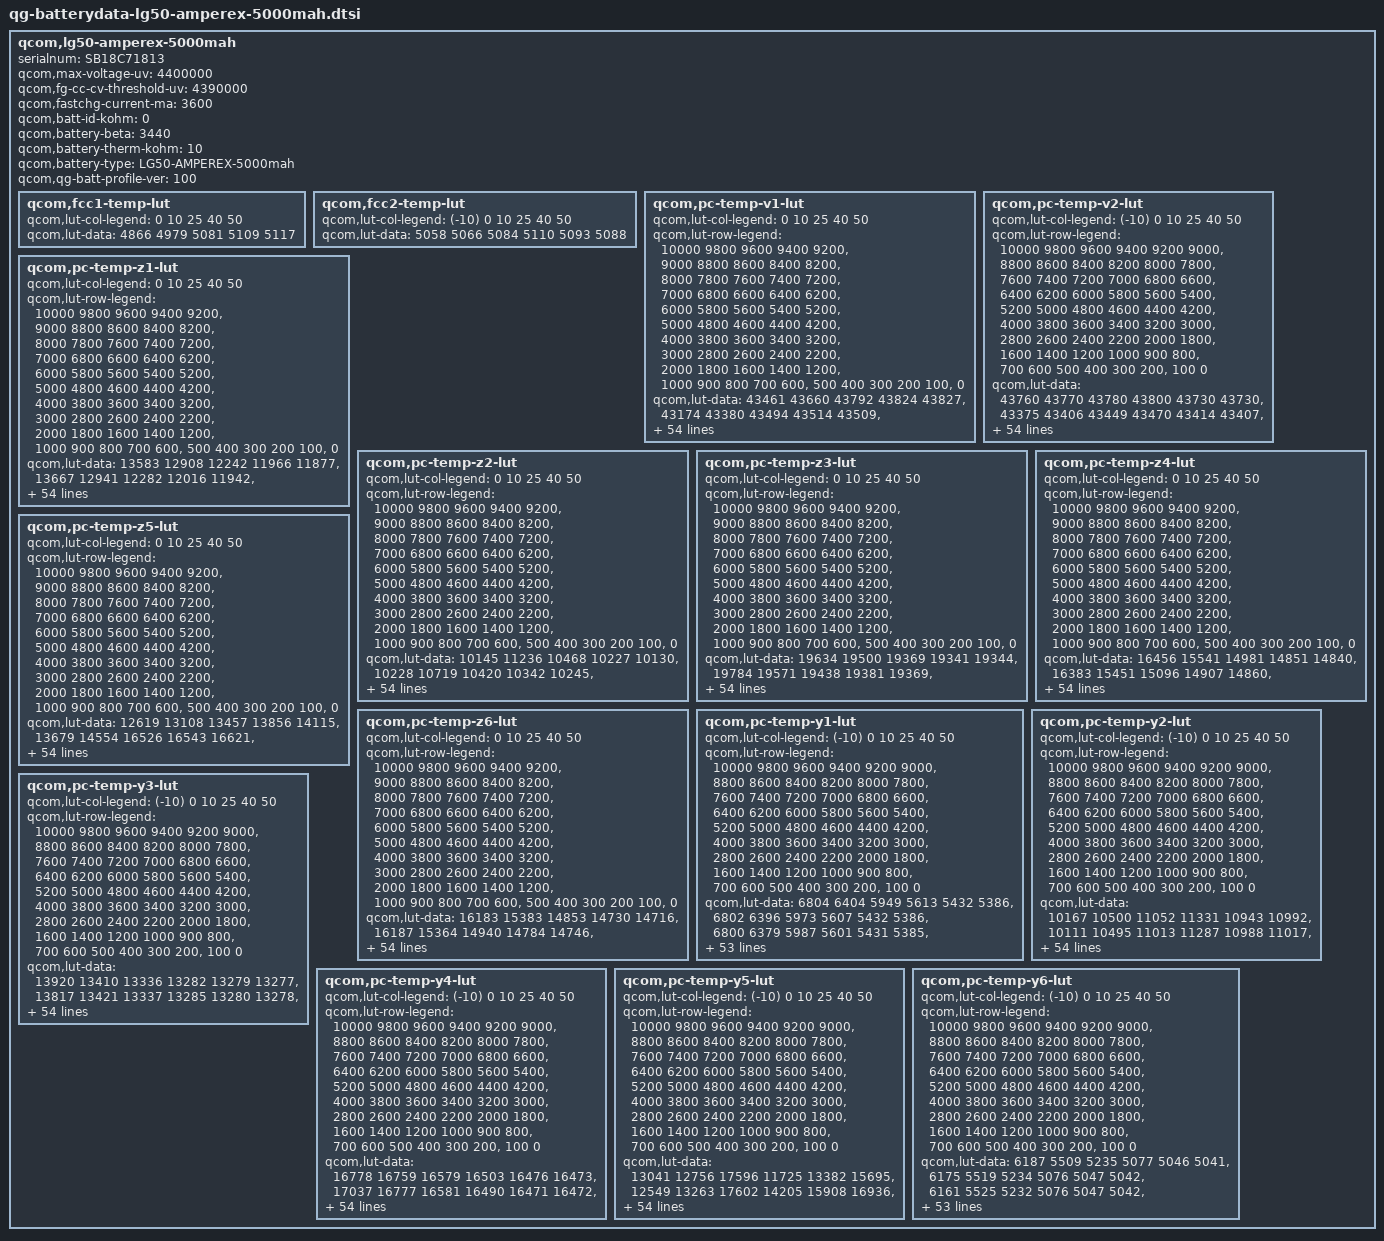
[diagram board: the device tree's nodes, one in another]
qcom,lg50-amperex-5000mah {
    /* 4130762_Lenovo_Liber_5000mAH_PMI632_averaged_MasterSlave_Jul30th2019 */
    serialnum = "SB18C71813";
    qcom,max-voltage-uv = <4400000>;
    qcom,fg-cc-cv-threshold-uv = <4390000>;
    qcom,fastchg-current-ma = <3600>;
    qcom,batt-id-kohm = <0>;
    qcom,battery-beta = <3440>;
    qcom,battery-therm-kohm = <10>;
    qcom,battery-type = "LG50-AMPEREX-5000mah";
    qcom,qg-batt-profile-ver = <100>;

	qcom,fcc1-temp-lut {
		qcom,lut-col-legend = <0 10 25 40 50>;
		qcom,lut-data = <4866 4979 5081 5109 5117>;
	};

	qcom,fcc2-temp-lut {
		qcom,lut-col-legend = <(-10) 0 10 25 40 50>;
		qcom,lut-data = <5058 5066 5084 5110 5093 5088>;
	};

	qcom,pc-temp-v1-lut {
		qcom,lut-col-legend = <0 10 25 40 50>;
		qcom,lut-row-legend = <10000 9800 9600 9400 9200>,
			<9000 8800 8600 8400 8200>,
			<8000 7800 7600 7400 7200>,
			<7000 6800 6600 6400 6200>,
			<6000 5800 5600 5400 5200>,
			<5000 4800 4600 4400 4200>,
			<4000 3800 3600 3400 3200>,
			<3000 2800 2600 2400 2200>,
			<2000 1800 1600 1400 1200>,
			<1000 900 800 700 600>,
			<500 400 300 200 100>,
			<0>;
		qcom,lut-data = <43461 43660 43792 43824 43827>,
			<43174 43380 43494 43514 43509>,
			<42919 43114 43234 43257 43253>,
			<42683 42863 42988 43014 43013>,
			<42454 42624 42744 42773 42776>,
			<42227 42390 42505 42537 42541>,
			<42005 42160 42274 42304 42310>,
			<41787 41936 42050 42074 42080>,
			<41571 41715 41830 41847 41853>,
			<41368 41497 41609 41623 41629>,
			<41190 41290 41388 41401 41408>,
			<41015 41103 41175 41186 41192>,
			<40802 40917 40975 40983 40981>,
			<40535 40702 40776 40785 40776>,
			<40287 40462 40562 40578 40576>,
			<40098 40247 40348 40369 40380>,
			<39933 40072 40160 40181 40195>,
			<39784 39916 39994 40019 40022>,
			<39648 39771 39840 39868 39859>,
			<39520 39640 39702 39722 39714>,
			<39394 39507 39566 39580 39579>,
			<39274 39370 39378 39394 39400>,
			<39155 39225 39109 39107 39105>,
			<39038 39032 38884 38857 38845>,
			<38925 38779 38739 38733 38730>,
			<38813 38596 38626 38645 38654>,
			<38703 38503 38535 38560 38569>,
			<38596 38436 38464 38479 38477>,
			<38482 38378 38396 38402 38388>,
			<38380 38330 38329 38322 38304>,
			<38316 38287 38267 38247 38226>,
			<38272 38247 38212 38182 38158>,
			<38237 38210 38162 38125 38102>,
			<38208 38175 38116 38071 38045>,
			<38184 38145 38074 38020 37989>,
			<38156 38112 38034 37970 37932>,
			<38127 38082 37995 37922 37877>,
			<38092 38049 37956 37875 37823>,
			<38045 37999 37905 37815 37756>,
			<37983 37922 37828 37728 37660>,
			<37904 37829 37733 37625 37550>,
			<37789 37715 37623 37518 37442>,
			<37654 37581 37492 37398 37323>,
			<37495 37426 37335 37246 37165>,
			<37349 37280 37193 37105 37031>,
			<37238 37172 37093 37015 36954>,
			<37204 37137 37059 36982 36921>,
			<37189 37118 37040 36959 36898>,
			<37159 37095 37021 36938 36875>,
			<37118 37059 36983 36889 36815>,
			<36950 36881 36780 36656 36557>,
			<36513 36454 36354 36222 36119>,
			<35937 35880 35780 35647 35542>,
			<35151 35089 34995 34861 34753>,
			<33909 33847 33773 33632 33519>,
			<30000 30000 30000 30000 30000>;
	};

	qcom,pc-temp-v2-lut {
		qcom,lut-col-legend = <(-10) 0 10 25 40 50>;
		qcom,lut-row-legend = <10000 9800 9600 9400 9200 9000>,
			<8800 8600 8400 8200 8000 7800>,
			<7600 7400 7200 7000 6800 6600>,
			<6400 6200 6000 5800 5600 5400>,
			<5200 5000 4800 4600 4400 4200>,
			<4000 3800 3600 3400 3200 3000>,
			<2800 2600 2400 2200 2000 1800>,
			<1600 1400 1200 1000 900 800>,
			<700 600 500 400 300 200>,
			<100 0>;
		qcom,lut-data = <43760 43770 43780 43800 43730 43730>,
			<43375 43406 43449 43470 43414 43407>,
			<43027 43079 43145 43168 43123 43110>,
			<42719 42793 42872 42900 42860 42846>,
			<42442 42545 42627 42662 42622 42609>,
			<42202 42306 42390 42429 42389 42378>,
			<42012 42067 42153 42193 42154 42144>,
			<41833 41833 41920 41958 41921 41912>,
			<41597 41597 41692 41729 41693 41683>,
			<41303 41359 41467 41502 41467 41457>,
			<41088 41148 41251 41280 41245 41236>,
			<40991 40983 41051 41066 41028 41020>,
			<40897 40821 40852 40856 40815 40809>,
			<40643 40608 40636 40650 40611 40605>,
			<40139 40347 40410 40447 40413 40406>,
			<39752 40088 40203 40247 40222 40216>,
			<39536 39828 40023 40047 40038 40033>,
			<39360 39586 39847 39861 39862 39859>,
			<39187 39397 39655 39710 39705 39699>,
			<39029 39237 39456 39571 39557 39549>,
			<38870 39073 39254 39396 39388 39382>,
			<38704 38899 39041 39168 39188 39191>,
			<38551 38734 38847 38950 38986 38998>,
			<38427 38594 38690 38765 38792 38803>,
			<38321 38470 38553 38601 38609 38613>,
			<38234 38348 38432 38471 38471 38471>,
			<38165 38219 38326 38365 38365 38363>,
			<38104 38113 38230 38270 38272 38268>,
			<38048 38045 38142 38183 38184 38178>,
			<37997 37992 38062 38105 38104 38096>,
			<37945 37947 37989 38034 38035 38025>,
			<37892 37909 37921 37967 37973 37962>,
			<37841 37871 37866 37907 37913 37901>,
			<37792 37828 37828 37851 37853 37841>,
			<37744 37782 37795 37798 37792 37780>,
			<37691 37737 37760 37743 37718 37701>,
			<37630 37693 37723 37686 37633 37602>,
			<37564 37644 37681 37625 37549 37505>,
			<37490 37580 37626 37557 37470 37414>,
			<37412 37505 37559 37484 37392 37326>,
			<37333 37420 37477 37404 37314 37247>,
			<37252 37321 37374 37312 37233 37169>,
			<37178 37207 37250 37196 37124 37061>,
			<37109 37081 37113 37064 36997 36933>,
			<37035 36965 36977 36940 36870 36811>,
			<36947 36860 36890 36881 36820 36763>,
			<36893 36818 36862 36867 36809 36753>,
			<36844 36773 36830 36852 36796 36741>,
			<36768 36717 36788 36821 36770 36714>,
			<36653 36618 36713 36741 36695 36621>,
			<36431 36413 36484 36448 36395 36309>,
			<36051 35998 36001 35930 35897 35805>,
			<35466 35386 35337 35244 35243 35145>,
			<34588 34495 34443 34292 34326 34230>,
			<33177 33073 33059 32869 32959 32918>,
			<28620 28431 27803 27803 27911 27810>;
	};

	qcom,pc-temp-z1-lut {
		qcom,lut-col-legend = <0 10 25 40 50>;
		qcom,lut-row-legend = <10000 9800 9600 9400 9200>,
			<9000 8800 8600 8400 8200>,
			<8000 7800 7600 7400 7200>,
			<7000 6800 6600 6400 6200>,
			<6000 5800 5600 5400 5200>,
			<5000 4800 4600 4400 4200>,
			<4000 3800 3600 3400 3200>,
			<3000 2800 2600 2400 2200>,
			<2000 1800 1600 1400 1200>,
			<1000 900 800 700 600>,
			<500 400 300 200 100>,
			<0>;
		qcom,lut-data = <13583 12908 12242 11966 11877>,
			<13667 12941 12282 12016 11942>,
			<13657 12956 12281 12022 11948>,
			<13619 12947 12279 12025 11950>,
			<13603 12916 12275 12025 11951>,
			<13611 12894 12267 12023 11952>,
			<13621 12887 12260 12021 11953>,
			<13608 12882 12252 12021 11955>,
			<13555 12867 12246 12022 11958>,
			<13526 12840 12243 12023 11963>,
			<13534 12823 12242 12028 11971>,
			<13545 12818 12240 12031 11975>,
			<13533 12815 12239 12033 11976>,
			<13456 12804 12238 12033 11977>,
			<13399 12782 12234 12033 11977>,
			<13397 12771 12229 12031 11976>,
			<13397 12769 12228 12030 11976>,
			<13396 12768 12230 12031 11977>,
			<13395 12770 12233 12032 11979>,
			<13394 12779 12237 12034 11980>,
			<13402 12788 12241 12036 11981>,
			<13422 12796 12242 12036 11982>,
			<13428 12804 12243 12036 11983>,
			<13411 12812 12244 12036 11985>,
			<13393 12820 12245 12037 11986>,
			<13397 12824 12248 12039 11987>,
			<13415 12824 12252 12042 11989>,
			<13424 12824 12257 12045 11991>,
			<13423 12825 12263 12048 11995>,
			<13420 12829 12266 12052 11997>,
			<13428 12834 12270 12055 12000>,
			<13469 12836 12276 12059 12003>,
			<13497 12839 12282 12063 12007>,
			<13484 12849 12288 12067 12011>,
			<13461 12873 12293 12072 12015>,
			<13457 12888 12299 12077 12018>,
			<13481 12890 12306 12081 12022>,
			<13509 12891 12314 12085 12025>,
			<13527 12897 12321 12089 12029>,
			<13541 12919 12329 12093 12031>,
			<13552 12941 12336 12097 12034>,
			<13559 12952 12344 12101 12037>,
			<13568 12963 12352 12105 12040>,
			<13587 12981 12357 12109 12043>,
			<13639 13002 12364 12113 12046>,
			<13623 12993 12377 12117 12047>,
			<13638 12992 12370 12116 12047>,
			<13620 12994 12370 12118 12049>,
			<13640 13014 12376 12120 12051>,
			<13630 13023 12382 12125 12056>,
			<13688 13022 12397 12130 12061>,
			<13741 13062 12400 12139 12068>,
			<13715 13062 12425 12149 12076>,
			<13745 13118 12443 12165 12091>,
			<13745 13118 12443 12165 12091>,
			<13745 13118 12443 12165 12091>;
	};

	qcom,pc-temp-z2-lut {
		qcom,lut-col-legend = <0 10 25 40 50>;
		qcom,lut-row-legend = <10000 9800 9600 9400 9200>,
			<9000 8800 8600 8400 8200>,
			<8000 7800 7600 7400 7200>,
			<7000 6800 6600 6400 6200>,
			<6000 5800 5600 5400 5200>,
			<5000 4800 4600 4400 4200>,
			<4000 3800 3600 3400 3200>,
			<3000 2800 2600 2400 2200>,
			<2000 1800 1600 1400 1200>,
			<1000 900 800 700 600>,
			<500 400 300 200 100>,
			<0>;
		qcom,lut-data = <10145 11236 10468 10227 10130>,
			<10228 10719 10420 10342 10245>,
			<10259 10387 10458 10396 10389>,
			<10275 10325 10481 10460 10458>,
			<10296 10305 10476 10471 10479>,
			<10338 10288 10454 10451 10486>,
			<10373 10270 10467 10434 10489>,
			<10377 10256 10845 10429 10471>,
			<10377 10250 11219 10426 10433>,
			<10377 10246 11236 10419 10409>,
			<10368 10245 11234 10408 10390>,
			<10349 10251 11237 10398 10382>,
			<10316 10260 11277 10389 10398>,
			<10247 10267 11311 10383 10420>,
			<10202 10272 11059 10393 10423>,
			<10245 10282 10550 10425 10421>,
			<10325 10312 10419 10435 10419>,
			<10340 10352 10431 10351 10415>,
			<10270 10383 10447 10267 10410>,
			<10208 10408 10466 10272 10382>,
			<10209 10431 10493 10309 10323>,
			<10221 10456 10542 10389 10328>,
			<10232 10476 10641 10691 10693>,
			<10240 10481 10695 10926 11022>,
			<10250 10482 10623 10750 10859>,
			<10262 10484 10520 10407 10495>,
			<10276 10490 10505 10330 10435>,
			<10292 10496 10509 10362 10701>,
			<10309 10495 10514 10407 10893>,
			<10325 10488 10523 10477 10844>,
			<10334 10483 10536 10548 10735>,
			<10340 10485 10547 10549 10626>,
			<10347 10489 10558 10505 10502>,
			<10355 10494 10567 10468 10402>,
			<10365 10501 10572 10447 10322>,
			<10378 10510 10578 10433 10269>,
			<10397 10521 10588 10433 10272>,
			<10418 10534 10604 10439 10307>,
			<10437 10547 10621 10453 10348>,
			<10456 10560 10641 10540 10405>,
			<10475 10571 10661 10623 10448>,
			<10493 10579 10680 10614 10447>,
			<10519 10588 10694 10592 10442>,
			<10564 10605 10695 10592 10509>,
			<10923 10743 10710 10589 10521>,
			<11039 10884 10744 10504 10408>,
			<10990 10863 10724 10484 10401>,
			<10831 11027 10772 10511 10425>,
			<10868 11064 10779 10524 10441>,
			<10942 11125 10804 10607 10516>,
			<10892 11168 10787 10524 10420>,
			<10797 11124 10730 10368 10226>,
			<10608 11051 10671 10301 10142>,
			<10351 10820 10541 10251 10089>,
			<10351 10820 10541 10251 10089>,
			<10351 10820 10541 10251 10089>;
	};

	qcom,pc-temp-z3-lut {
		qcom,lut-col-legend = <0 10 25 40 50>;
		qcom,lut-row-legend = <10000 9800 9600 9400 9200>,
			<9000 8800 8600 8400 8200>,
			<8000 7800 7600 7400 7200>,
			<7000 6800 6600 6400 6200>,
			<6000 5800 5600 5400 5200>,
			<5000 4800 4600 4400 4200>,
			<4000 3800 3600 3400 3200>,
			<3000 2800 2600 2400 2200>,
			<2000 1800 1600 1400 1200>,
			<1000 900 800 700 600>,
			<500 400 300 200 100>,
			<0>;
		qcom,lut-data = <19634 19500 19369 19341 19344>,
			<19784 19571 19438 19381 19369>,
			<19792 19616 19452 19394 19384>,
			<19791 19624 19458 19403 19392>,
			<19787 19627 19460 19410 19399>,
			<19754 19628 19461 19415 19405>,
			<19713 19621 19463 19417 19409>,
			<19696 19610 19473 19417 19410>,
			<19686 19600 19482 19417 19410>,
			<19677 19590 19483 19416 19410>,
			<19668 19581 19483 19415 19408>,
			<19660 19569 19483 19414 19405>,
			<19667 19559 19481 19405 19402>,
			<19716 19558 19476 19396 19397>,
			<19758 19558 19461 19396 19394>,
			<19772 19558 19436 19398 19391>,
			<19781 19540 19424 19399 19388>,
			<19778 19515 19420 19391 19384>,
			<19729 19507 19416 19379 19379>,
			<19681 19503 19410 19371 19370>,
			<19670 19502 19405 19364 19357>,
			<19665 19505 19407 19363 19354>,
			<19663 19511 19425 19381 19369>,
			<19665 19521 19436 19396 19382>,
			<19667 19535 19428 19385 19371>,
			<19671 19543 19416 19363 19346>,
			<19675 19542 19411 19357 19343>,
			<19680 19540 19409 19356 19368>,
			<19684 19538 19408 19356 19390>,
			<19688 19535 19411 19367 19398>,
			<19687 19532 19415 19385 19403>,
			<19678 19528 19418 19388 19402>,
			<19666 19524 19420 19388 19393>,
			<19653 19521 19421 19388 19383>,
			<19638 19518 19421 19385 19375>,
			<19627 19515 19420 19381 19369>,
			<19619 19511 19418 19376 19362>,
			<19611 19507 19412 19369 19355>,
			<19604 19505 19408 19367 19353>,
			<19598 19504 19406 19368 19353>,
			<19591 19502 19405 19369 19354>,
			<19586 19500 19403 19368 19356>,
			<19580 19498 19401 19366 19359>,
			<19571 19491 19400 19367 19364>,
			<19495 19459 19393 19367 19364>,
			<19469 19435 19377 19353 19350>,
			<19450 19434 19375 19350 19345>,
			<19310 19397 19361 19341 19334>,
			<19307 19388 19352 19338 19328>,
			<19303 19384 19349 19332 19327>,
			<19305 19386 19366 19348 19342>,
			<19327 19378 19374 19367 19361>,
			<19331 19335 19374 19369 19364>,
			<19337 19347 19365 19361 19360>,
			<19337 19347 19365 19361 19360>,
			<19337 19347 19365 19361 19360>;
	};

	qcom,pc-temp-z4-lut {
		qcom,lut-col-legend = <0 10 25 40 50>;
		qcom,lut-row-legend = <10000 9800 9600 9400 9200>,
			<9000 8800 8600 8400 8200>,
			<8000 7800 7600 7400 7200>,
			<7000 6800 6600 6400 6200>,
			<6000 5800 5600 5400 5200>,
			<5000 4800 4600 4400 4200>,
			<4000 3800 3600 3400 3200>,
			<3000 2800 2600 2400 2200>,
			<2000 1800 1600 1400 1200>,
			<1000 900 800 700 600>,
			<500 400 300 200 100>,
			<0>;
		qcom,lut-data = <16456 15541 14981 14851 14840>,
			<16383 15451 15096 14907 14860>,
			<16210 15353 15029 14897 14866>,
			<15931 15239 14934 14857 14839>,
			<15719 15111 14882 14827 14816>,
			<15587 15014 14845 14802 14795>,
			<15482 14949 14805 14781 14777>,
			<15391 14899 14756 14764 14762>,
			<15314 14863 14714 14749 14748>,
			<15244 14836 14692 14735 14735>,
			<15181 14811 14677 14721 14721>,
			<15121 14787 14663 14712 14711>,
			<15056 14767 14648 14706 14705>,
			<14984 14755 14640 14701 14701>,
			<14916 14746 14657 14698 14698>,
			<14843 14741 14693 14696 14696>,
			<14778 14740 14701 14693 14693>,
			<14765 14739 14691 14688 14689>,
			<14788 14733 14680 14682 14685>,
			<14808 14717 14673 14677 14680>,
			<14803 14705 14667 14674 14676>,
			<14786 14699 14676 14678 14679>,
			<14772 14695 14731 14740 14747>,
			<14760 14711 14776 14796 14810>,
			<14751 14776 14794 14808 14815>,
			<14747 14812 14806 14815 14818>,
			<14745 14806 14804 14814 14813>,
			<14745 14796 14787 14798 14770>,
			<14752 14784 14769 14777 14729>,
			<14762 14769 14753 14753 14709>,
			<14763 14755 14738 14727 14696>,
			<14759 14743 14723 14710 14688>,
			<14753 14732 14710 14698 14684>,
			<14750 14722 14699 14690 14681>,
			<14747 14713 14690 14684 14679>,
			<14744 14706 14684 14680 14677>,
			<14739 14700 14680 14677 14676>,
			<14734 14695 14677 14675 14676>,
			<14731 14694 14676 14675 14676>,
			<14728 14693 14678 14682 14686>,
			<14727 14693 14679 14688 14698>,
			<14728 14692 14678 14687 14693>,
			<14728 14690 14676 14683 14684>,
			<14718 14689 14675 14682 14686>,
			<14720 14683 14669 14674 14680>,
			<14717 14676 14658 14661 14659>,
			<14736 14674 14654 14658 14656>,
			<14889 14704 14658 14654 14654>,
			<14888 14709 14657 14638 14640>,
			<14886 14708 14653 14634 14625>,
			<14882 14711 14650 14648 14655>,
			<14880 14736 14658 14652 14660>,
			<14892 14794 14664 14657 14664>,
			<14904 14790 14681 14671 14674>,
			<14904 14790 14681 14671 14674>,
			<14904 14790 14681 14671 14674>;
	};

	qcom,pc-temp-z5-lut {
		qcom,lut-col-legend = <0 10 25 40 50>;
		qcom,lut-row-legend = <10000 9800 9600 9400 9200>,
			<9000 8800 8600 8400 8200>,
			<8000 7800 7600 7400 7200>,
			<7000 6800 6600 6400 6200>,
			<6000 5800 5600 5400 5200>,
			<5000 4800 4600 4400 4200>,
			<4000 3800 3600 3400 3200>,
			<3000 2800 2600 2400 2200>,
			<2000 1800 1600 1400 1200>,
			<1000 900 800 700 600>,
			<500 400 300 200 100>,
			<0>;
		qcom,lut-data = <12619 13108 13457 13856 14115>,
			<13679 14554 16526 16543 16621>,
			<14021 15746 17704 17740 18183>,
			<14209 16631 18529 18933 19542>,
			<14257 17334 19255 20039 20867>,
			<14205 17919 19851 21092 22199>,
			<14146 18430 20755 21992 23376>,
			<14161 18858 22488 22642 24271>,
			<14253 19178 24738 23232 25060>,
			<14348 19419 27173 24143 26020>,
			<14405 19730 30024 25483 27194>,
			<14472 20172 33514 26080 28184>,
			<14907 20804 38878 25572 28799>,
			<16961 22184 42422 24951 29354>,
			<19442 24793 37557 26047 30203>,
			<22069 25979 27616 29732 31374>,
			<24631 23856 25101 31175 32445>,
			<24967 21186 25689 28790 33513>,
			<22201 21111 26562 26387 34239>,
			<19735 22439 27491 26326 32822>,
			<19945 24360 28906 26587 28799>,
			<21012 27509 33844 28068 27998>,
			<22401 32187 49932 39428 36990>,
			<24498 39409 59419 48740 45106>,
			<27291 50941 48719 40834 38004>,
			<30662 56487 32338 24860 22524>,
			<34973 51954 26894 19607 18670>,
			<39679 44812 24442 18286 20664>,
			<46098 40915 23650 17801 23508>,
			<51705 38265 24209 19541 27823>,
			<51839 36608 25317 22846 32323>,
			<47636 35574 26742 25169 32801>,
			<42592 34924 28875 26981 31477>,
			<37604 34932 31360 28783 30722>,
			<32649 35320 35082 31161 30834>,
			<30054 35547 37916 33005 30977>,
			<28652 35157 37871 33139 30976>,
			<27708 34601 37205 33019 30919>,
			<26996 34639 36636 33038 30915>,
			<26450 35263 36284 34514 31460>,
			<26233 35645 35817 36009 32030>,
			<26163 35094 34064 33579 31254>,
			<26228 33966 31973 28970 29704>,
			<27695 32208 32776 30306 33400>,
			<23925 29158 31860 31262 35277>,
			<22490 26702 27290 25550 26737>,
			<21393 25854 26449 23586 23527>,
			<12457 18210 21456 21118 19981>,
			<12382 17095 19357 22958 21369>,
			<12352 16969 19604 22552 25803>,
			<12497 17201 24445 26564 26235>,
			<12869 15720 22741 25367 24416>,
			<12690 13270 21128 22905 21559>,
			<12534 13395 18058 18104 17625>,
			<12534 13395 18058 18104 17625>,
			<12534 13395 18058 18104 17625>;
	};

	qcom,pc-temp-z6-lut {
		qcom,lut-col-legend = <0 10 25 40 50>;
		qcom,lut-row-legend = <10000 9800 9600 9400 9200>,
			<9000 8800 8600 8400 8200>,
			<8000 7800 7600 7400 7200>,
			<7000 6800 6600 6400 6200>,
			<6000 5800 5600 5400 5200>,
			<5000 4800 4600 4400 4200>,
			<4000 3800 3600 3400 3200>,
			<3000 2800 2600 2400 2200>,
			<2000 1800 1600 1400 1200>,
			<1000 900 800 700 600>,
			<500 400 300 200 100>,
			<0>;
		qcom,lut-data = <16183 15383 14853 14730 14716>,
			<16187 15364 14940 14784 14746>,
			<16133 15333 14916 14783 14753>,
			<15976 15288 14881 14773 14748>,
			<15842 15222 14859 14764 14744>,
			<15749 15166 14841 14757 14739>,
			<15670 15125 14824 14749 14733>,
			<15609 15092 14808 14742 14728>,
			<15560 15065 14795 14736 14723>,
			<15515 15044 14786 14730 14718>,
			<15470 15024 14779 14725 14713>,
			<15429 15003 14772 14720 14708>,
			<15396 14984 14764 14713 14703>,
			<15371 14972 14758 14706 14699>,
			<15346 14963 14756 14705 14696>,
			<15321 14954 14755 14704 14693>,
			<15296 14944 14752 14703 14690>,
			<15276 14933 14746 14696 14686>,
			<15259 14925 14739 14687 14681>,
			<15245 14917 14733 14681 14674>,
			<15233 14914 14728 14675 14665>,
			<15223 14915 14734 14677 14665>,
			<15219 14918 14768 14714 14702>,
			<15217 14931 14791 14745 14736>,
			<15216 14967 14794 14743 14733>,
			<15217 14986 14795 14737 14723>,
			<15221 14985 14793 14731 14716>,
			<15227 14981 14785 14724 14712>,
			<15235 14977 14778 14718 14708>,
			<15243 14970 14773 14715 14705>,
			<15243 14964 14769 14712 14702>,
			<15238 14958 14766 14709 14698>,
			<15233 14953 14762 14704 14692>,
			<15227 14950 14758 14700 14686>,
			<15221 14946 14756 14697 14682>,
			<15218 14944 14754 14694 14678>,
			<15216 14943 14751 14690 14674>,
			<15215 14942 14747 14686 14670>,
			<15216 14943 14746 14685 14669>,
			<15220 14946 14748 14688 14673>,
			<15224 14950 14749 14691 14678>,
			<15231 14953 14748 14691 14678>,
			<15237 14956 14748 14689 14676>,
			<15242 14957 14748 14690 14679>,
			<15223 14949 14744 14687 14678>,
			<15215 14938 14733 14674 14661>,
			<15212 14936 14730 14671 14658>,
			<15207 14931 14725 14665 14651>,
			<15207 14931 14720 14657 14642>,
			<15210 14932 14718 14652 14636>,
			<15220 14940 14728 14668 14656>,
			<15239 14953 14738 14682 14672>,
			<15258 14965 14745 14688 14678>,
			<15287 14983 14753 14693 14684>,
			<15287 14983 14753 14693 14684>,
			<15287 14983 14753 14693 14684>;
	};

	qcom,pc-temp-y1-lut {
		qcom,lut-col-legend = <(-10) 0 10 25 40 50>;
		qcom,lut-row-legend = <10000 9800 9600 9400 9200 9000>,
			<8800 8600 8400 8200 8000 7800>,
			<7600 7400 7200 7000 6800 6600>,
			<6400 6200 6000 5800 5600 5400>,
			<5200 5000 4800 4600 4400 4200>,
			<4000 3800 3600 3400 3200 3000>,
			<2800 2600 2400 2200 2000 1800>,
			<1600 1400 1200 1000 900 800>,
			<700 600 500 400 300 200>,
			<100 0>;
		qcom,lut-data = <6804 6404 5949 5613 5432 5386>,
			<6802 6396 5973 5607 5432 5386>,
			<6800 6379 5987 5601 5431 5385>,
			<6799 6360 5994 5595 5431 5384>,
			<6799 6344 5996 5590 5429 5383>,
			<6799 6338 5997 5585 5428 5382>,
			<6814 6338 5983 5582 5426 5382>,
			<6835 6338 5966 5578 5424 5381>,
			<6832 6340 5965 5574 5423 5380>,
			<6809 6344 5966 5569 5422 5379>,
			<6798 6347 5967 5566 5421 5379>,
			<6799 6343 5964 5564 5420 5379>,
			<6801 6339 5961 5562 5419 5380>,
			<6804 6340 5960 5560 5418 5380>,
			<6808 6344 5960 5559 5418 5381>,
			<6810 6349 5961 5558 5418 5381>,
			<6810 6354 5964 5559 5419 5382>,
			<6810 6358 5967 5560 5419 5382>,
			<6810 6358 5967 5560 5420 5383>,
			<6810 6358 5964 5559 5420 5383>,
			<6808 6357 5963 5560 5421 5384>,
			<6790 6356 5963 5561 5422 5384>,
			<6771 6355 5963 5563 5422 5385>,
			<6776 6363 5963 5566 5423 5386>,
			<6791 6382 5965 5568 5424 5388>,
			<6795 6386 5967 5571 5426 5389>,
			<6779 6371 5970 5574 5429 5389>,
			<6757 6356 5973 5577 5431 5390>,
			<6740 6350 5975 5581 5434 5392>,
			<6723 6348 5978 5585 5436 5395>,
			<6723 6347 5981 5589 5439 5398>,
			<6754 6351 5984 5593 5441 5400>,
			<6780 6353 5986 5597 5444 5403>,
			<6779 6353 5989 5600 5446 5404>,
			<6777 6353 5991 5603 5448 5406>,
			<6768 6348 5993 5606 5450 5408>,
			<6734 6326 5996 5609 5452 5409>,
			<6710 6310 5999 5612 5454 5411>,
			<6714 6328 6002 5614 5455 5412>,
			<6726 6355 6005 5616 5455 5413>,
			<6743 6357 6009 5618 5455 5414>,
			<6775 6343 6014 5619 5455 5415>,
			<6778 6346 6019 5619 5457 5417>,
			<6769 6362 6024 5620 5460 5419>,
			<6796 6366 6031 5635 5467 5422>,
			<6827 6351 6043 5645 5470 5424>,
			<6815 6351 6045 5645 5469 5424>,
			<6863 6352 6048 5648 5469 5426>,
			<6816 6358 6032 5649 5468 5425>,
			<6817 6388 6059 5648 5470 5426>,
			<6823 6397 6066 5652 5473 5428>,
			<6825 6411 6064 5660 5479 5433>,
			<6835 6380 6075 5682 5487 5440>,
			<6879 6432 6090 5714 5498 5450>,
			<6879 6432 6090 5714 5498 5450>,
			<6879 6432 6090 5714 5498 5450>;
	};

	qcom,pc-temp-y2-lut {
		qcom,lut-col-legend = <(-10) 0 10 25 40 50>;
		qcom,lut-row-legend = <10000 9800 9600 9400 9200 9000>,
			<8800 8600 8400 8200 8000 7800>,
			<7600 7400 7200 7000 6800 6600>,
			<6400 6200 6000 5800 5600 5400>,
			<5200 5000 4800 4600 4400 4200>,
			<4000 3800 3600 3400 3200 3000>,
			<2800 2600 2400 2200 2000 1800>,
			<1600 1400 1200 1000 900 800>,
			<700 600 500 400 300 200>,
			<100 0>;
		qcom,lut-data = <10167 10500 11052 11331 10943 10992>,
			<10111 10495 11013 11287 10988 11017>,
			<10087 10495 10975 11244 11015 11024>,
			<10087 10497 10940 11203 11029 11017>,
			<10105 10503 10910 11166 11034 11001>,
			<10134 10510 10886 11131 11034 10979>,
			<10205 10523 10868 11098 10985 10934>,
			<10306 10535 10854 11069 10920 10892>,
			<10400 10537 10839 11042 10905 10891>,
			<10501 10537 10824 11016 10900 10906>,
			<10542 10540 10816 11008 10894 10911>,
			<10534 10669 10813 11012 10883 10885>,
			<10524 10823 10811 11016 10873 10849>,
			<10563 10841 10842 11009 10870 10831>,
			<10698 10843 10941 10989 10868 10818>,
			<10744 10847 11011 10987 10868 10815>,
			<10280 10870 11048 11039 10873 10824>,
			<9759 10907 11076 11108 10884 10842>,
			<9703 10947 11099 11175 10927 10865>,
			<9694 10998 11118 11241 11020 10906>,
			<9688 11045 11141 11264 11113 10979>,
			<9683 11098 11170 11271 11225 11175>,
			<9679 11132 11203 11278 11290 11317>,
			<9677 11126 11237 11286 11254 11252>,
			<9675 11111 11274 11296 11190 11127>,
			<9674 11108 11309 11315 11182 11099>,
			<9672 11135 11346 11350 11219 11111>,
			<9671 11157 11367 11384 11243 11130>,
			<9669 11155 11369 11413 11239 11164>,
			<9668 11147 11370 11439 11233 11207>,
			<9666 11132 11376 11458 11248 11227>,
			<9665 11094 11400 11474 11319 11237>,
			<9664 11025 11413 11478 11356 11247>,
			<9664 10628 11398 11466 11343 11260>,
			<9663 9997 11368 11450 11319 11271>,
			<9662 9793 11337 11443 11290 11268>,
			<9661 9738 11300 11438 11252 11249>,
			<9661 9708 11260 11428 11237 11224>,
			<9661 9693 11216 11395 11239 11177>,
			<9660 9683 11170 11368 11244 11133>,
			<9660 9676 11130 11365 11261 11123>,
			<9659 9671 11091 11363 11288 11118>,
			<9659 9667 11019 11367 11282 11103>,
			<9659 9664 10915 11367 11243 11075>,
			<9658 9661 10821 11322 11148 11003>,
			<9658 9660 10735 11242 11008 10868>,
			<9658 9659 10658 11221 11005 10869>,
			<9657 9658 10590 11225 11047 10923>,
			<9657 9657 10539 11236 11041 10959>,
			<9657 9656 10502 11199 11069 10889>,
			<9656 9656 10435 11188 11031 10808>,
			<9655 9655 9901 11127 10886 10749>,
			<9653 9654 9677 10986 10825 10671>,
			<9650 9653 9661 10898 10710 10542>,
			<9650 9653 9661 10898 10710 10542>,
			<9650 9653 9661 10898 10710 10542>;
	};

	qcom,pc-temp-y3-lut {
		qcom,lut-col-legend = <(-10) 0 10 25 40 50>;
		qcom,lut-row-legend = <10000 9800 9600 9400 9200 9000>,
			<8800 8600 8400 8200 8000 7800>,
			<7600 7400 7200 7000 6800 6600>,
			<6400 6200 6000 5800 5600 5400>,
			<5200 5000 4800 4600 4400 4200>,
			<4000 3800 3600 3400 3200 3000>,
			<2800 2600 2400 2200 2000 1800>,
			<1600 1400 1200 1000 900 800>,
			<700 600 500 400 300 200>,
			<100 0>;
		qcom,lut-data = <13920 13410 13336 13282 13279 13277>,
			<13817 13421 13337 13285 13280 13278>,
			<13752 13432 13338 13288 13281 13279>,
			<13716 13441 13339 13290 13283 13280>,
			<13700 13448 13341 13292 13284 13281>,
			<13697 13450 13342 13293 13284 13282>,
			<13727 13447 13344 13292 13285 13282>,
			<13768 13444 13345 13291 13285 13282>,
			<13734 13446 13346 13291 13285 13283>,
			<13576 13453 13347 13291 13285 13283>,
			<13495 13456 13347 13292 13286 13283>,
			<13510 13432 13349 13297 13286 13284>,
			<13529 13403 13351 13301 13286 13285>,
			<13528 13404 13351 13302 13287 13286>,
			<13513 13416 13349 13302 13288 13286>,
			<13493 13421 13348 13302 13290 13286>,
			<13461 13412 13349 13302 13291 13285>,
			<13434 13399 13349 13302 13292 13285>,
			<13434 13393 13347 13303 13293 13286>,
			<13441 13388 13342 13303 13294 13289>,
			<13443 13382 13337 13303 13294 13290>,
			<13440 13371 13331 13301 13292 13289>,
			<13434 13362 13325 13297 13290 13288>,
			<13423 13357 13321 13294 13286 13285>,
			<13408 13354 13317 13290 13282 13280>,
			<13404 13349 13316 13289 13282 13279>,
			<13415 13339 13314 13288 13282 13279>,
			<13432 13332 13314 13288 13282 13279>,
			<13450 13331 13314 13289 13281 13278>,
			<13473 13330 13313 13289 13280 13277>,
			<13495 13330 13313 13290 13280 13277>,
			<13514 13336 13309 13290 13281 13277>,
			<13536 13340 13307 13290 13281 13278>,
			<13565 13340 13309 13290 13281 13279>,
			<13600 13340 13312 13291 13281 13280>,
			<13634 13343 13314 13290 13281 13280>,
			<13667 13357 13316 13290 13281 13280>,
			<13703 13372 13318 13290 13281 13280>,
			<13741 13380 13320 13291 13281 13280>,
			<13783 13388 13321 13291 13281 13280>,
			<13825 13405 13323 13291 13282 13281>,
			<13869 13439 13324 13292 13285 13283>,
			<13922 13484 13325 13292 13285 13283>,
			<13984 13546 13327 13290 13285 13283>,
			<14034 13620 13327 13289 13280 13280>,
			<14066 13687 13332 13290 13285 13285>,
			<14119 13770 13337 13294 13289 13289>,
			<14198 13864 13344 13300 13293 13292>,
			<14276 13966 13355 13303 13295 13294>,
			<14385 14067 13372 13305 13295 13292>,
			<14523 14169 13380 13302 13290 13287>,
			<14751 14292 13410 13303 13289 13288>,
			<15235 14520 13499 13306 13295 13291>,
			<16969 14957 13728 13321 13304 13303>,
			<16969 14957 13728 13321 13304 13303>,
			<16969 14957 13728 13321 13304 13303>;
	};

	qcom,pc-temp-y4-lut {
		qcom,lut-col-legend = <(-10) 0 10 25 40 50>;
		qcom,lut-row-legend = <10000 9800 9600 9400 9200 9000>,
			<8800 8600 8400 8200 8000 7800>,
			<7600 7400 7200 7000 6800 6600>,
			<6400 6200 6000 5800 5600 5400>,
			<5200 5000 4800 4600 4400 4200>,
			<4000 3800 3600 3400 3200 3000>,
			<2800 2600 2400 2200 2000 1800>,
			<1600 1400 1200 1000 900 800>,
			<700 600 500 400 300 200>,
			<100 0>;
		qcom,lut-data = <16778 16759 16579 16503 16476 16473>,
			<17037 16777 16581 16490 16471 16472>,
			<17195 16795 16584 16482 16467 16471>,
			<17277 16811 16586 16478 16465 16469>,
			<17307 16826 16588 16476 16463 16468>,
			<17312 16838 16589 16475 16463 16468>,
			<17235 16849 16588 16478 16464 16468>,
			<17131 16857 16588 16483 16466 16469>,
			<17173 16855 16589 16488 16468 16469>,
			<17408 16842 16596 16493 16470 16470>,
			<17555 16839 16605 16495 16472 16470>,
			<17589 16973 16615 16495 16475 16471>,
			<17606 17132 16629 16494 16478 16473>,
			<17491 17122 16654 16500 16482 16475>,
			<17100 17025 16692 16515 16486 16480>,
			<16923 16933 16717 16529 16491 16484>,
			<16973 16850 16731 16540 16496 16489>,
			<17029 16788 16738 16553 16503 16496>,
			<17016 16769 16724 16584 16521 16505>,
			<16955 16760 16683 16624 16546 16518>,
			<16893 16746 16641 16627 16553 16527>,
			<16827 16719 16592 16583 16550 16535>,
			<16778 16688 16554 16537 16544 16539>,
			<16769 16663 16539 16501 16516 16517>,
			<16765 16640 16530 16472 16472 16476>,
			<16763 16615 16525 16468 16462 16465>,
			<16762 16583 16523 16468 16462 16465>,
			<16761 16563 16521 16468 16462 16465>,
			<16758 16565 16517 16469 16465 16467>,
			<16755 16570 16512 16473 16471 16473>,
			<16754 16575 16509 16477 16479 16479>,
			<16763 16579 16507 16482 16488 16488>,
			<16770 16584 16507 16486 16494 16496>,
			<16769 16609 16511 16488 16498 16506>,
			<16768 16648 16519 16490 16501 16513>,
			<16768 16671 16527 16489 16497 16509>,
			<16771 16684 16538 16485 16481 16492>,
			<16774 16695 16548 16483 16474 16481>,
			<16771 16705 16556 16480 16473 16477>,
			<16766 16712 16564 16479 16473 16475>,
			<16765 16713 16569 16483 16478 16481>,
			<16771 16711 16573 16488 16488 16497>,
			<16780 16705 16575 16487 16486 16494>,
			<16793 16696 16576 16482 16474 16479>,
			<16808 16689 16563 16464 16453 16449>,
			<16797 16695 16565 16479 16465 16468>,
			<16818 16714 16583 16493 16492 16507>,
			<16838 16743 16611 16518 16529 16547>,
			<16864 16788 16654 16558 16572 16589>,
			<16885 16842 16719 16590 16588 16586>,
			<16887 16868 16728 16538 16502 16508>,
			<16868 16856 16742 16513 16486 16488>,
			<16873 16842 16789 16535 16488 16488>,
			<17261 16876 16874 16589 16504 16500>,
			<17261 16876 16874 16589 16504 16500>,
			<17261 16876 16874 16589 16504 16500>;
	};

	qcom,pc-temp-y5-lut {
		qcom,lut-col-legend = <(-10) 0 10 25 40 50>;
		qcom,lut-row-legend = <10000 9800 9600 9400 9200 9000>,
			<8800 8600 8400 8200 8000 7800>,
			<7600 7400 7200 7000 6800 6600>,
			<6400 6200 6000 5800 5600 5400>,
			<5200 5000 4800 4600 4400 4200>,
			<4000 3800 3600 3400 3200 3000>,
			<2800 2600 2400 2200 2000 1800>,
			<1600 1400 1200 1000 900 800>,
			<700 600 500 400 300 200>,
			<100 0>;
		qcom,lut-data = <13041 12756 17596 11725 13382 15695>,
			<12549 13263 17602 14205 15908 16936>,
			<12322 13959 17605 15836 17716 17981>,
			<12326 14667 17605 16787 18893 18779>,
			<12528 15209 17602 17227 19523 19281>,
			<12908 15408 17596 17315 19686 19436>,
			<15791 15356 17540 16676 19095 19208>,
			<19422 15243 17417 15728 18158 18782>,
			<18788 15075 17168 15193 17583 18315>,
			<14292 14777 16626 14785 17153 17736>,
			<12011 14453 16047 14703 16710 17396>,
			<14848 14039 15346 15601 16144 17291>,
			<18326 13712 14822 16509 15693 17192>,
			<18666 14943 14858 16102 15537 16883>,
			<18478 18976 15167 14989 15446 16272>,
			<18095 20676 15722 14638 15428 15681>,
			<15799 19322 17609 14738 15493 15038>,
			<13426 17880 19716 14923 15553 14620>,
			<13530 18185 20923 15289 15430 14657>,
			<14375 19281 21843 16007 15159 14853>,
			<14705 19677 22016 17414 15464 15424>,
			<14502 19444 21452 20910 18700 18185>,
			<14140 19222 20692 23056 21213 20332>,
			<13493 20048 19909 21970 21087 20321>,
			<12548 21995 19145 20160 20754 20193>,
			<12246 22321 19000 19457 20498 19972>,
			<12255 19172 19188 19108 20317 19443>,
			<12273 16290 19495 18993 20047 18756>,
			<12408 15827 20280 19346 19012 17714>,
			<12672 15591 21252 19964 17769 16669>,
			<12740 15658 21065 20504 17661 16508>,
			<12650 16490 19204 21058 18094 16574>,
			<12576 17118 18081 21642 18668 16705>,
			<12808 15993 18605 22410 19562 17918>,
			<13260 14008 19479 22950 20466 19864>,
			<13372 13615 20017 22953 20861 21344>,
			<13345 13860 20441 22878 21112 22717>,
			<13301 14023 20595 22807 21161 23185>,
			<13225 13915 20484 22754 20538 21706>,
			<13101 13749 20264 22669 19881 20026>,
			<12906 13729 19974 21913 20147 20167>,
			<12589 13768 19536 20990 21186 21223>,
			<12554 13692 18935 21438 23315 23414>,
			<12715 13513 18459 20345 23981 24669>,
			<12901 13580 17793 19910 17815 19979>,
			<13036 13117 17628 17478 17527 18116>,
			<12842 13343 17326 18121 17460 16671>,
			<13315 13434 16744 19004 16902 16068>,
			<13381 13669 16820 18382 16318 15602>,
			<13732 13791 17580 18066 16157 14977>,
			<13680 14007 17542 18406 17546 15731>,
			<13549 13628 14971 20354 16601 15698>,
			<12875 13502 13673 18915 18292 15770>,
			<11143 12973 13435 20992 22278 22724>,
			<11143 12973 13435 20992 22278 22724>,
			<11143 12973 13435 20992 22278 22724>;
	};

	qcom,pc-temp-y6-lut {
		qcom,lut-col-legend = <(-10) 0 10 25 40 50>;
		qcom,lut-row-legend = <10000 9800 9600 9400 9200 9000>,
			<8800 8600 8400 8200 8000 7800>,
			<7600 7400 7200 7000 6800 6600>,
			<6400 6200 6000 5800 5600 5400>,
			<5200 5000 4800 4600 4400 4200>,
			<4000 3800 3600 3400 3200 3000>,
			<2800 2600 2400 2200 2000 1800>,
			<1600 1400 1200 1000 900 800>,
			<700 600 500 400 300 200>,
			<100 0>;
		qcom,lut-data = <6187 5509 5235 5077 5046 5041>,
			<6175 5519 5234 5076 5047 5042>,
			<6161 5525 5232 5076 5047 5042>,
			<6148 5529 5230 5075 5047 5043>,
			<6136 5531 5229 5075 5048 5043>,
			<6129 5531 5227 5075 5048 5044>,
			<6127 5529 5225 5075 5049 5044>,
			<6124 5526 5223 5076 5049 5044>,
			<6112 5522 5223 5076 5050 5045>,
			<6076 5518 5223 5077 5051 5045>,
			<6058 5517 5224 5079 5052 5046>,
			<6079 5536 5226 5081 5053 5047>,
			<6104 5558 5230 5084 5054 5048>,
			<6077 5556 5235 5087 5056 5049>,
			<5974 5540 5243 5090 5058 5050>,
			<5915 5521 5249 5094 5060 5052>,
			<5903 5496 5254 5097 5062 5053>,
			<5895 5473 5257 5102 5065 5055>,
			<5890 5465 5252 5111 5071 5059>,
			<5886 5461 5236 5122 5079 5065>,
			<5880 5455 5220 5122 5081 5067>,
			<5869 5444 5202 5108 5078 5068>,
			<5861 5434 5188 5092 5074 5068>,
			<5862 5431 5181 5079 5063 5060>,
			<5866 5429 5177 5069 5048 5045>,
			<5873 5427 5176 5067 5045 5041>,
			<5888 5423 5177 5067 5045 5040>,
			<5908 5420 5177 5067 5045 5040>,
			<5927 5426 5178 5068 5046 5041>,
			<5948 5442 5179 5070 5047 5042>,
			<5969 5458 5180 5072 5049 5044>,
			<5991 5477 5180 5074 5053 5046>,
			<6015 5497 5181 5076 5055 5049>,
			<6041 5517 5186 5078 5057 5053>,
			<6070 5539 5194 5079 5058 5056>,
			<6098 5563 5202 5078 5056 5055>,
			<6128 5592 5210 5078 5052 5050>,
			<6158 5624 5219 5078 5050 5047>,
			<6189 5657 5228 5078 5050 5046>,
			<6221 5694 5239 5078 5050 5046>,
			<6256 5736 5250 5079 5053 5049>,
			<6292 5785 5263 5081 5057 5055>,
			<6335 5842 5279 5082 5057 5054>,
			<6386 5909 5299 5081 5054 5050>,
			<6442 5980 5309 5076 5045 5040>,
			<6472 6047 5336 5083 5052 5050>,
			<6522 6123 5365 5090 5063 5063>,
			<6589 6209 5402 5102 5077 5077>,
			<6660 6306 5453 5116 5091 5091>,
			<6752 6404 5512 5126 5095 5089>,
			<6863 6497 5552 5110 5067 5063>,
			<7046 6597 5613 5105 5063 5059>,
			<7441 6773 5761 5119 5069 5062>,
			<8962 7139 6044 5152 5081 5075>,
			<8962 7139 6044 5152 5081 5075>,
			<8962 7139 6044 5152 5081 5075>;
	};

};
